# STM32F40x register map
File version: 1.5
Registers are 32-bit, read-write, reset 0x0 unless marked. A register's access mark holds for its fields unless they carry their own. Offsets are from the block's base; [hi:lo] are bit positions; lines under a group give offsets from that group; {n}, {i} and the like mark numbered series.

## SPI1（串行外设接口） — 串行外设接口：全双工同步串行通信 | Serial peripheral interface
Base 0x40013000
Same registers: I2S2ext（I2S2扩展） 0x40003400, SPI2（串行外设接口） 0x40003800, SPI3（串行外设接口） 0x40003C00, I2S3ext（I2S3扩展） 0x40004000
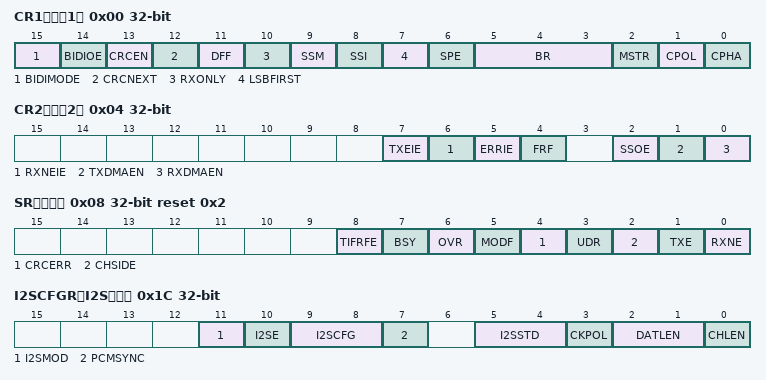
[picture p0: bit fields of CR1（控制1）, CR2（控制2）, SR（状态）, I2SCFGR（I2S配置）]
0x00 CR1（控制1） — 控制1：时钟极性/相位/波特率/主从/帧格式 | control register 1
  [15] BIDIMODE — Bidirectional data mode enable
  [14] BIDIOE — Output enable in bidirectional mode
  [13] CRCEN — Hardware CRC calculation enable
  [12] CRCNEXT — CRC transfer next
  [11] DFF — Data frame format
  [10] RXONLY — Receive only
  [9] SSM — Software slave management
  [8] SSI — Internal slave select
  [7] LSBFIRST — Frame format
  [6] SPE — SPI enable
  [5:3] BR — Baud rate control
  [2] MSTR — Master selection
  [1] CPOL — Clock polarity
  [0] CPHA — Clock phase
0x04 CR2（控制2） — 控制2：中断/DMA/数据帧长度 | control register 2
  [7] TXEIE — Tx buffer empty interrupt enable
  [6] RXNEIE — RX buffer not empty interrupt enable
  [5] ERRIE — Error interrupt enable
  [4] FRF — Frame format
  [2] SSOE — SS output enable
  [1] TXDMAEN — Tx buffer DMA enable
  [0] RXDMAEN — Rx buffer DMA enable
0x08 SR（状态） access per field reset 0x2 — 状态：发送/接收就绪与溢出/忙标志 | status register
  [8] TIFRFE ro — TI frame format error
  [7] BSY ro — Busy flag
  [6] OVR ro — Overrun flag
  [5] MODF ro — Mode fault
  [4] CRCERR rw — CRC error flag
  [3] UDR ro — Underrun flag
  [2] CHSIDE ro — Channel side
  [1] TXE ro — Transmit buffer empty
  [0] RXNE ro — Receive buffer not empty
0x0C DR（数据） — 数据：收发数据 | data register
  [15:0] DR — Data register
0x10 CRCPR（CRC多项式） reset 0x7 — CRC 多项式寄存器 | CRC polynomial register
  [15:0] CRCPOLY — CRC polynomial register
0x14 RXCRCR（RX CRC校验） ro — 接收 CRC 寄存器 | RX CRC register
  [15:0] RxCRC
0x18 TXCRCR（TX CRC校验） ro — 发送 CRC 寄存器 | TX CRC register
  [15:0] TxCRC
0x1C I2SCFGR（I2S配置） — I2S 模式配置 | I2S configuration register
  [11] I2SMOD — I2S mode selection
  [10] I2SE — I2S Enable
  [9:8] I2SCFG — I2S configuration mode
  [7] PCMSYNC — PCM frame synchronization
  [5:4] I2SSTD — I2S standard selection
  [3] CKPOL — Steady state clock polarity
  [2:1] DATLEN — Data length to be transferred
  [0] CHLEN — Channel length (number of bits per audio channel)
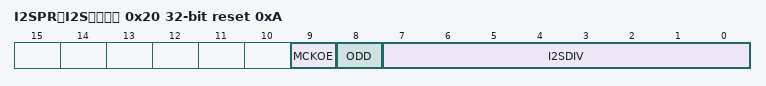
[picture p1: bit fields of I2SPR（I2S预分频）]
0x20 I2SPR（I2S预分频） reset 0xA — I2S 时钟预分频 | I2S prescaler register
  [9] MCKOE — Master clock output enable
  [8] ODD — Odd factor for the prescaler
  [7:0] I2SDIV — I2S Linear prescaler

## ADC1（模数转换1） — 模数转换器：将模拟电压转为数字量 | Analog-to-digital converter
Base 0x40012000
Same registers: ADC2（模数转换2） 0x40012100, ADC3（模数转换3） 0x40012200
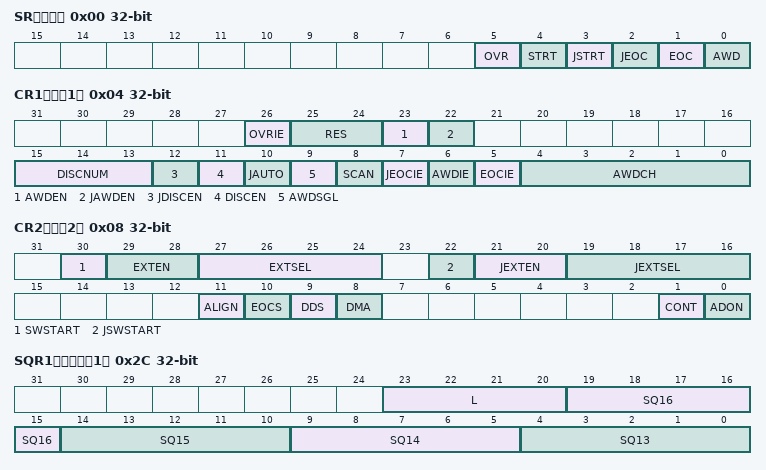
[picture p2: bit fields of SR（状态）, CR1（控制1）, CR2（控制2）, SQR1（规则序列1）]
0x00 SR（状态） — 状态：转换结束 EOC 等标志 | status register
  [5] OVR — Overrun
  [4] STRT — Regular channel start flag
  [3] JSTRT — Injected channel start flag
  [2] JEOC — Injected channel end of conversion
  [1] EOC — Regular channel end of conversion
  [0] AWD — Analog watchdog flag
0x04 CR1（控制1） — 控制1：分辨率/扫描/间断模式/中断 | control register 1
  [26] OVRIE — Overrun interrupt enable
  [25:24] RES — Resolution
  [23] AWDEN — Analog watchdog enable on regular channels
  [22] JAWDEN — Analog watchdog enable on injected channels
  [15:13] DISCNUM — Discontinuous mode channel count
  [12] JDISCEN — Discontinuous mode on injected channels
  [11] DISCEN — Discontinuous mode on regular channels
  [10] JAUTO — Automatic injected group conversion
  [9] AWDSGL — Enable the watchdog on a single channel in scan mode
  [8] SCAN — Scan mode
  [7] JEOCIE — Interrupt enable for injected channels
  [6] AWDIE — Analog watchdog interrupt enable
  [5] EOCIE — Interrupt enable for EOC
  [4:0] AWDCH — Analog watchdog channel select bits
0x08 CR2（控制2） — 控制2：启动转换/对齐/触发源/DMA | control register 2
  [30] SWSTART — Start conversion of regular channels
  [29:28] EXTEN — External trigger enable for regular channels
  [27:24] EXTSEL — External event select for regular group
  [22] JSWSTART — Start conversion of injected channels
  [21:20] JEXTEN — External trigger enable for injected channels
  [19:16] JEXTSEL — External event select for injected group
  [11] ALIGN — Data alignment
  [10] EOCS — End of conversion selection
  [9] DDS — DMA disable selection (for single ADC mode)
  [8] DMA — Direct memory access mode (for single ADC mode)
  [1] CONT — Continuous conversion
  [0] ADON — A/D Converter ON / OFF
0x0C SMPR1（采样时间1） — 采样时间1：通道 10~17 采样周期 | sample time register 1
  [31:0] SMPx_x — Sample time bits
0x10 SMPR2（采样时间2） — 采样时间2：通道 0~9 采样周期 | sample time register 2
  [31:0] SMPx_x — Sample time bits
{0x10+4i} JOFR{i}（注入偏移{i}） (i=1..4) — 注入通道 {i} 数据偏移 | injected channel data offset register x
  [11:0] JOFFSET{i} — Data offset for injected channel x
0x24 HTR（上限阈值） reset 0xFFF — 模拟看门狗高阈值 | watchdog higher threshold register
  [11:0] HT — Analog watchdog higher threshold
0x28 LTR（下限阈值） — 模拟看门狗低阈值 | watchdog lower threshold register
  [11:0] LT — Analog watchdog lower threshold
0x2C SQR1（规则序列1） — 规则组序列：转换总数与通道 16~26 | regular sequence register 1
  [23:20] L — Regular channel sequence length
  [5n-61:5n-65] SQ{n} (n=13..16) — {n}th conversion in regular sequence
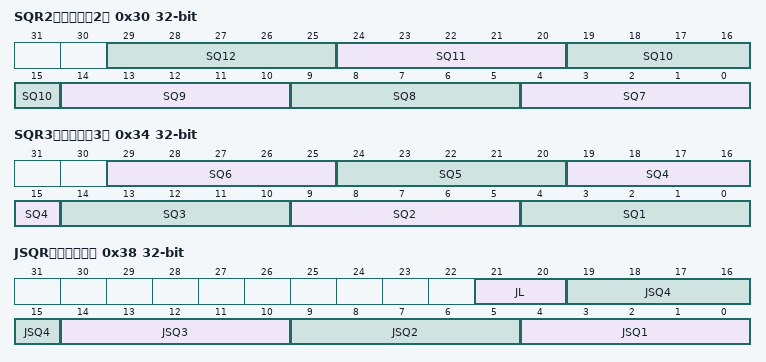
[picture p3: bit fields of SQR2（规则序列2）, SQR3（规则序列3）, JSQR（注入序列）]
0x30 SQR2（规则序列2） — 规则组序列：通道 7~15 | regular sequence register 2
  [5n-31:5n-35] SQ{n} (n=7..12) — {n}th conversion in regular sequence
0x34 SQR3（规则序列3） — 规则组序列：通道 0~6 | regular sequence register 3
  [29:25] SQ6 — 6th conversion in regular sequence
  [24:20] SQ5 — 5th conversion in regular sequence
  [19:15] SQ4 — 4th conversion in regular sequence
  [14:10] SQ3 — 3rd conversion in regular sequence
  [9:5] SQ2 — 2nd conversion in regular sequence
  [4:0] SQ1 — 1st conversion in regular sequence
0x38 JSQR（注入序列） — 注入组序列：长度与通道 | injected sequence register
  [21:20] JL — Injected sequence length
  [19:15] JSQ4 — 4th conversion in injected sequence
  [14:10] JSQ3 — 3rd conversion in injected sequence
  [9:5] JSQ2 — 2nd conversion in injected sequence
  [4:0] JSQ1 — 1st conversion in injected sequence
{0x38+4i} JDR{i}（注入数据{i}） ro (i=1..4) — 注入通道 {i} 转换结果 | injected data register x
  [15:0] JDATA — Injected data
0x4C DR（数据） ro — 数据：规则组转换结果 | regular data register
  [15:0] DATA — Regular data
